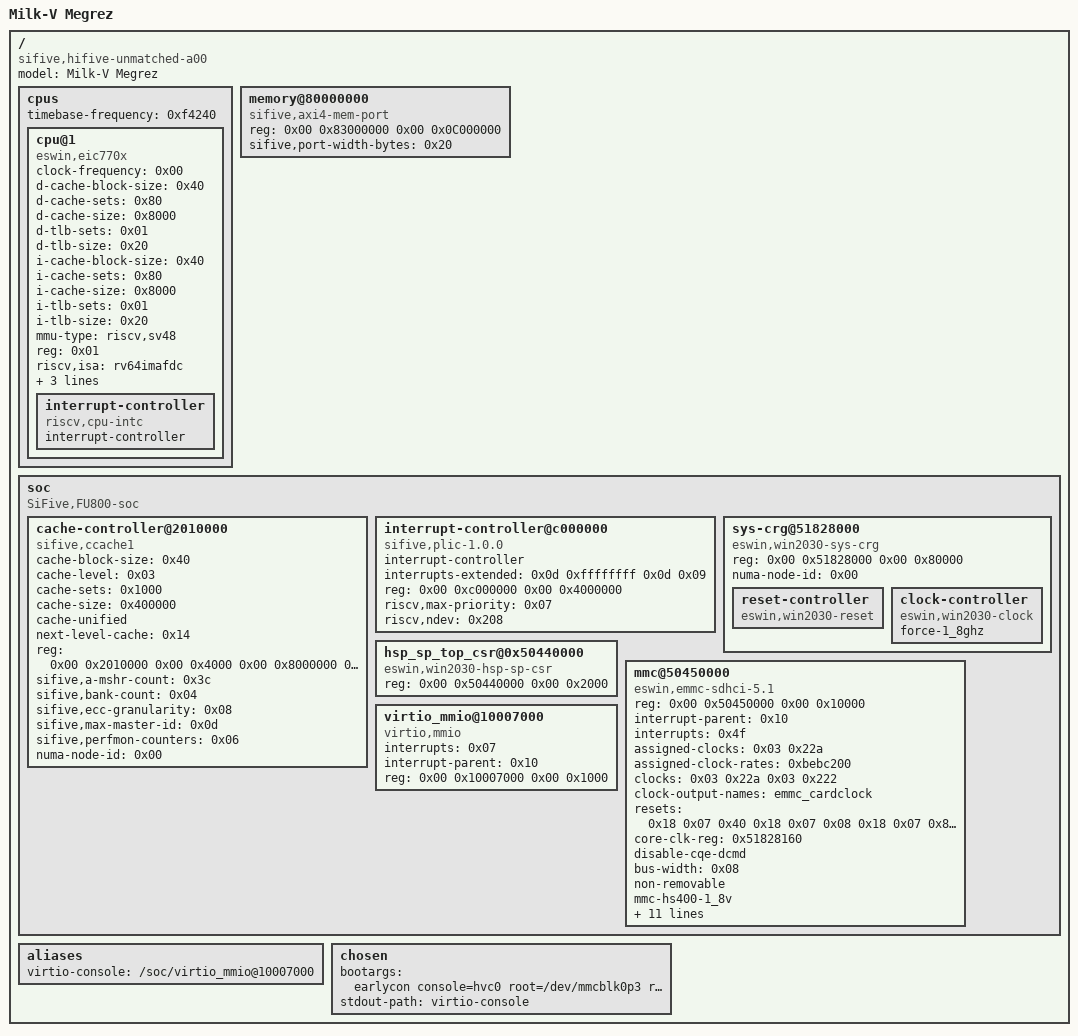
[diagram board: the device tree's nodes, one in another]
/dts-v1/;

/ {
	#address-cells = <0x02>;
	#size-cells = <0x02>;
	compatible = "sifive,hifive-unmatched-a00\0sifive,fu740-c000\0sifive,fu740\0eswin,eic7700";
	model = "Milk-V Megrez";
	
	cpus {
		#address-cells = <0x01>;
		#size-cells = <0x00>;
		timebase-frequency = <0xf4240>;
		
		cpu@1 {
			clock-frequency = <0x00>;
			compatible = "eswin,eic770x\0riscv";
			d-cache-block-size = <0x40>;
			d-cache-sets = <0x80>;
			d-cache-size = <0x8000>;
			d-tlb-sets = <0x01>;
			d-tlb-size = <0x20>;
			device_type = "cpu";
			// hardware-exec-breakpoint-count = <0x04>;
			// hwpf-distanceBits = <0x06>;
			// hwpf-hitCacheThrdBits = <0x05>;
			// hwpf-hitMSHRThrdBits = <0x04>;
			// hwpf-l2pfPoolSize = <0x0a>;
			// hwpf-nIssQEnt = <0x06>;
			// hwpf-nPrefetchQueueEntries = <0x08>;
			// hwpf-nStreams = <0x10>;
			// hwpf-qFullnessThrdBits = <0x04>;
			// hwpf-windowBits = <0x06>;
			i-cache-block-size = <0x40>;
			i-cache-sets = <0x80>;
			i-cache-size = <0x8000>;
			i-tlb-sets = <0x01>;
			i-tlb-size = <0x20>;
			mmu-type = "riscv,sv48";
			reg = <0x01>;
			riscv,isa = "rv64imafdc";
			status = "okay";
			timebase-frequency = <0xf4240>;
			tlb-split;
			clocks = <0x03 0x1f5>;
			phandle = <0x4b>;
			
			interrupt-controller {
				#interrupt-cells = <0x01>;
				compatible = "riscv,cpu-intc";
				interrupt-controller;
				phandle = <0x0d>;
			};
		};
	};
	
	memory@80000000 {
		compatible = "sifive,axi4-mem-port\0sifive,axi4-port\0sifive,mem-port";
		device_type = "memory";
		reg = <0x00 0x83000000 0x00 0x0C000000>;
		sifive,port-width-bytes = <0x20>;
		phandle = <0x14>;
	};
	
	soc {
		#address-cells = <0x02>;
		#size-cells = <0x02>;
		compatible = "SiFive,FU800-soc\0fu800-soc\0sifive-soc\0simple-bus";
		ranges;

		cache-controller@2010000 {
			cache-block-size = <0x40>;
			cache-level = <0x03>;
			cache-sets = <0x1000>;
			cache-size = <0x400000>;
			cache-unified;
			compatible = "sifive,ccache1\0cache\0sifive,fu740-c000-ccache";
			// interrupt-parent = <0x10>;
			// interrupts = <0x01 0x03 0x04 0x02>;
			next-level-cache = <0x14>;
			reg = <0x00 0x2010000 0x00 0x4000 0x00 0x8000000 0x00 0x400000>;
			reg-names = "control\0sideband";
			sifive,a-mshr-count = <0x3c>;
			sifive,bank-count = <0x04>;
			sifive,ecc-granularity = <0x08>;
			sifive,max-master-id = <0x0d>;
			sifive,perfmon-counters = <0x06>;
			numa-node-id = <0x00>;
			phandle = <0x15>;
		};
		
		interrupt-controller@c000000 {
			#interrupt-cells = <0x01>;
			compatible = "sifive,plic-1.0.0";
			interrupt-controller;
			interrupts-extended = <0x0d 0xffffffff 0x0d 0x09>;
			reg = <0x00 0xc000000 0x00 0x4000000>;
			reg-names = "control";
			riscv,max-priority = <0x07>;
			riscv,ndev = <0x208>;
			phandle = <0x10>;
		};

		sys-crg@51828000 {
			compatible = "eswin,win2030-sys-crg\0syscon\0simple-mfd";
			reg = <0x00 0x51828000 0x00 0x80000>;
			numa-node-id = <0x00>;
			phandle = <0x16>;

			reset-controller {
				compatible = "eswin,win2030-reset";
				#reset-cells = <0x02>;
				status = "okay";
				phandle = <0x18>;
			};

			clock-controller {
				compatible = "eswin,win2030-clock";
				#clock-cells = <0x01>;
				status = "okay";
				force-1_8ghz;
				phandle = <0x03>;
			};
		};

		hsp_sp_top_csr@0x50440000 {
			compatible = "eswin,win2030-hsp-sp-csr\0syscon";
			#size-cells = <0x02>;
			reg = <0x00 0x50440000 0x00 0x2000>;
			phandle = <0x1a>;
		};

		mmc@50450000 {
			compatible = "eswin,emmc-sdhci-5.1";
			reg = <0x00 0x50450000 0x00 0x10000>;
			interrupt-parent = <0x10>;
			interrupts = <0x4f>;
			assigned-clocks = <0x03 0x22a>;
			assigned-clock-rates = <0xbebc200>;
			clocks = <0x03 0x22a 0x03 0x222>;
			clock-names = "clk_xin\0clk_ahb";
			clock-output-names = "emmc_cardclock";
			#clock-cells = <0x00>;
			resets = <0x18 0x07 0x40 0x18 0x07 0x08 0x18 0x07 0x80000 0x18 0x07 0x800000>;
			reset-names = "txrx_rst\0phy_rst\0prstn\0arstn";
			core-clk-reg = <0x51828160>;
			disable-cqe-dcmd;
			bus-width = <0x08>;
			non-removable;
			mmc-hs400-1_8v;
			max-frequency = <0xbebc200>;
			#size-cells = <0x02>;
			//iommus = <0x19 0x0f>;
			//tbus = <0x02>;
			//dma-ranges = <0x00 0x00 0x00 0xc0000000 0x01 0x00>;
			eswin,hsp_sp_csr = <0x1a 0x1038 0x508 0x50c>;
			eswin,syscrg_csr = <0x16 0x160 0x148 0x14c>;
			status = "okay";
			numa-node-id = <0x00>;
			dma-noncoherent;
			delay_code = <0x17>;
			drive-impedance-ohm = <0x32>;
			enable-cmd-pullup;
			enable-data-pullup;
			//pinctrl-names = "default";
			//pinctrl-0 = <0x2b>;
			no-sdio;
			no-sd;
		};

		virtio_mmio@10007000 {
			interrupts = <0x07>;
			interrupt-parent = <0x10>;
			reg = <0x00 0x10007000 0x00 0x1000>;
			compatible = "virtio,mmio";
		};
	};

	aliases {
		virtio-console = "/soc/virtio_mmio@10007000";
	};
	
	chosen {
		bootargs = "earlycon console=hvc0 root=/dev/mmcblk0p3 rootfstype=ext4 rw rootwait init=/bin/bash";
		stdout-path = "virtio-console";
	};
};
